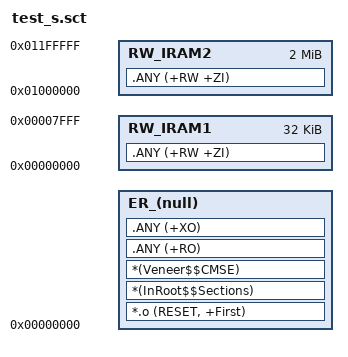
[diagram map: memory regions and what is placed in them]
; *************************************************************
; *** Scatter-Loading Description File generated by uVision ***
; *************************************************************

LR_(null) 0x00000000 0x00000000  {    ; load region size_region
  ER_(null) 0x00000000 0x00000000  {  ; load address = execution address
   *.o (RESET, +First)
   *(InRoot$$Sections)
   *(Veneer$$CMSE)                   ; check with partition.h
   .ANY (+RO)
   .ANY (+XO)
  }
  RW_IRAM1 0x00000000 0x00008000  {  ; RW data
   .ANY (+RW +ZI)
  }
  RW_IRAM2 0x01000000 0x00200000  {
   .ANY (+RW +ZI)
  }
}

